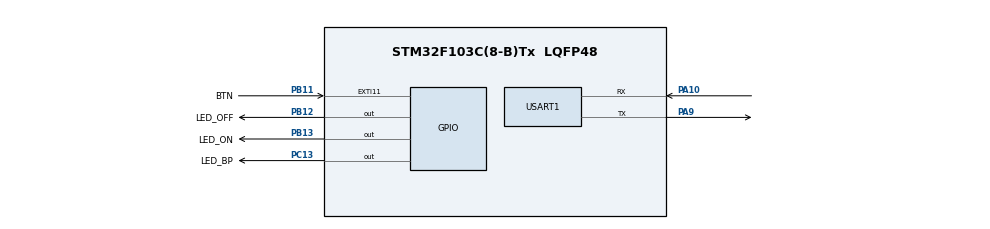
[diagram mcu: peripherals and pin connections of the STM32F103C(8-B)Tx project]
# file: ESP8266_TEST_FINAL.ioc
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FREERTOS.Tasks01=defaultTask,24,128,StartDefaultTask,Default,NULL,Dynamic,NULL,NULL
FREERTOS.configTOTAL_HEAP_SIZE=8000
FREERTOS.configUSE_NEWLIB_REENTRANT=1
FREERTOS.configUSE_TICKLESS_IDLE=1
Mcu.Family=STM32F1
Mcu.Name=STM32F103C(8-B)Tx
Mcu.Package=LQFP48
NVIC.EXTI15_10_IRQn=true\:5\:0\:false\:false\:true\:true\:true\:true\:true
NVIC.PriorityGroup=NVIC_PRIORITYGROUP_4
NVIC.TIM1_UP_IRQn=true\:15\:0\:false\:false\:true\:false\:false\:true\:true
NVIC.TimeBase=TIM1_UP_IRQn
NVIC.TimeBaseIP=TIM1
NVIC.USART1_IRQn=true\:5\:0\:false\:false\:true\:true\:true\:true\:true
PA10.Mode=Asynchronous
PA10.Signal=USART1_RX
PA13.Mode=Serial_Wire
PA13.Signal=SYS_JTMS-SWDIO
PA14.Mode=Serial_Wire
PA14.Signal=SYS_JTCK-SWCLK
PA9.Mode=Asynchronous
PA9.Signal=USART1_TX
PB11.GPIO_Label=BTN
PB11.GPIO_PuPd=GPIO_PULLDOWN
PB11.Signal=GPXTI11
PB12.GPIO_Label=LED_OFF
PB12.Signal=GPIO_Output
PB13.GPIO_Label=LED_ON
PB13.Signal=GPIO_Output
PC13-TAMPER-RTC.GPIO_Label=LED_BP
PC13-TAMPER-RTC.Signal=GPIO_Output
PC14-OSC32_IN.Mode=LSE-External-Oscillator
PC14-OSC32_IN.Signal=RCC_OSC32_IN
PC15-OSC32_OUT.Mode=LSE-External-Oscillator
PC15-OSC32_OUT.Signal=RCC_OSC32_OUT
PD0-OSC_IN.Mode=HSE-External-Oscillator
PD0-OSC_IN.Signal=RCC_OSC_IN
PD1-OSC_OUT.Mode=HSE-External-Oscillator
PD1-OSC_OUT.Signal=RCC_OSC_OUT
ProjectManager.HeapSize=0x200
ProjectManager.StackSize=0x400
ProjectManager.TargetToolchain=STM32CubeIDE
RCC.APB1Freq_Value=8000000
RCC.APB2Freq_Value=8000000
USART1.VirtualMode=VM_ASYNC
VP_FREERTOS_VS_CMSIS_V2.Mode=CMSIS_V2
VP_SYS_VS_tim1.Mode=TIM1
board=custom

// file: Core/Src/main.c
/* USER CODE BEGIN Header */
/**
  ******************************************************************************
  * @file           : main.c
  * @brief          : Main program body
  ******************************************************************************
  * @attention
  *
  * Copyright (c) 2025 STMicroelectronics.
  * All rights reserved.
  *
  * This software is licensed under terms that can be found in the LICENSE file
  * in the root directory of this software component.
  * If no LICENSE file comes with this software, it is provided AS-IS.
  *
  ******************************************************************************
  */
/* USER CODE END Header */
#include "main.h"
#include "cmsis_os.h"

/* USER CODE BEGIN Includes */
#include "esp8266.h"
/* USER CODE END Includes */

UART_HandleTypeDef huart1;

/* Definitions for defaultTask */
osThreadId_t defaultTaskHandle;
const osThreadAttr_t defaultTask_attributes = {
  .name = "defaultTask",
  .stack_size = 128 * 4,
  .priority = (osPriority_t) osPriorityNormal,
};

void SystemClock_Config(void);
static void MX_GPIO_Init(void);
static void MX_USART1_UART_Init(void);
void StartDefaultTask(void *argument);

int main(void)
{

  /* MCU Configuration--------------------------------------------------------*/

  /* Reset of all peripherals, Initializes the Flash interface and the Systick. */
  HAL_Init();

  /* Configure the system clock */
  SystemClock_Config();

  /* Initialize all configured peripherals */
  MX_GPIO_Init();
  MX_USART1_UART_Init();
  /* USER CODE BEGIN 2 */
  esp8266_init();
  /* USER CODE END 2 */

  /* Init scheduler */
  osKernelInitialize();

  /* Create the thread(s) */
  /* creation of defaultTask */
  defaultTaskHandle = osThreadNew(StartDefaultTask, NULL, &defaultTask_attributes);

  /* Start scheduler */
  osKernelStart();

  /* We should never get here as control is now taken by the scheduler */

  /* Infinite loop */
  while (1)
  {

  }
}

void SystemClock_Config(void)
{
  RCC_OscInitTypeDef RCC_OscInitStruct = {0};
  RCC_ClkInitTypeDef RCC_ClkInitStruct = {0};

  /** Initializes the RCC Oscillators according to the specified parameters
  * in the RCC_OscInitTypeDef structure.
  */
  RCC_OscInitStruct.OscillatorType = RCC_OSCILLATORTYPE_HSI;
  RCC_OscInitStruct.HSIState = RCC_HSI_ON;
  RCC_OscInitStruct.HSICalibrationValue = RCC_HSICALIBRATION_DEFAULT;
  RCC_OscInitStruct.PLL.PLLState = RCC_PLL_NONE;
  if (HAL_RCC_OscConfig(&RCC_OscInitStruct) != HAL_OK)
  {
    Error_Handler();
  }

  /** Initializes the CPU, AHB and APB buses clocks
  */
  RCC_ClkInitStruct.ClockType = RCC_CLOCKTYPE_HCLK|RCC_CLOCKTYPE_SYSCLK
                              |RCC_CLOCKTYPE_PCLK1|RCC_CLOCKTYPE_PCLK2;
  RCC_ClkInitStruct.SYSCLKSource = RCC_SYSCLKSOURCE_HSI;
  RCC_ClkInitStruct.AHBCLKDivider = RCC_SYSCLK_DIV1;
  RCC_ClkInitStruct.APB1CLKDivider = RCC_HCLK_DIV1;
  RCC_ClkInitStruct.APB2CLKDivider = RCC_HCLK_DIV1;

  if (HAL_RCC_ClockConfig(&RCC_ClkInitStruct, FLASH_LATENCY_0) != HAL_OK)
  {
    Error_Handler();
  }
}

static void MX_USART1_UART_Init(void)
{

  huart1.Instance = USART1;
  huart1.Init.BaudRate = 115200;
  huart1.Init.WordLength = UART_WORDLENGTH_8B;
  huart1.Init.StopBits = UART_STOPBITS_1;
  huart1.Init.Parity = UART_PARITY_NONE;
  huart1.Init.Mode = UART_MODE_TX_RX;
  huart1.Init.HwFlowCtl = UART_HWCONTROL_NONE;
  huart1.Init.OverSampling = UART_OVERSAMPLING_16;
  if (HAL_UART_Init(&huart1) != HAL_OK)
  {
    Error_Handler();
  }

}

static void MX_GPIO_Init(void)
{
  GPIO_InitTypeDef GPIO_InitStruct = {0};

  /* GPIO Ports Clock Enable */
  __HAL_RCC_GPIOC_CLK_ENABLE();
  __HAL_RCC_GPIOD_CLK_ENABLE();
  __HAL_RCC_GPIOB_CLK_ENABLE();
  __HAL_RCC_GPIOA_CLK_ENABLE();

  /*Configure GPIO pin Output Level */
  HAL_GPIO_WritePin(LED_BP_GPIO_Port, LED_BP_Pin, GPIO_PIN_RESET);

  /*Configure GPIO pin Output Level */
  HAL_GPIO_WritePin(GPIOB, LED_OFF_Pin|LED_ON_Pin, GPIO_PIN_RESET);

  /*Configure GPIO pin : LED_BP_Pin */
  GPIO_InitStruct.Pin = LED_BP_Pin;
  GPIO_InitStruct.Mode = GPIO_MODE_OUTPUT_PP;
  GPIO_InitStruct.Pull = GPIO_NOPULL;
  GPIO_InitStruct.Speed = GPIO_SPEED_FREQ_LOW;
  HAL_GPIO_Init(LED_BP_GPIO_Port, &GPIO_InitStruct);

  /*Configure GPIO pin : BTN_Pin */
  GPIO_InitStruct.Pin = BTN_Pin;
  GPIO_InitStruct.Mode = GPIO_MODE_IT_RISING;
  GPIO_InitStruct.Pull = GPIO_PULLDOWN;
  HAL_GPIO_Init(BTN_GPIO_Port, &GPIO_InitStruct);

  /*Configure GPIO pins : LED_OFF_Pin LED_ON_Pin */
  GPIO_InitStruct.Pin = LED_OFF_Pin|LED_ON_Pin;
  GPIO_InitStruct.Mode = GPIO_MODE_OUTPUT_PP;
  GPIO_InitStruct.Pull = GPIO_NOPULL;
  GPIO_InitStruct.Speed = GPIO_SPEED_FREQ_LOW;
  HAL_GPIO_Init(GPIOB, &GPIO_InitStruct);

  /* EXTI interrupt init*/
  HAL_NVIC_SetPriority(EXTI15_10_IRQn, 5, 0);
  HAL_NVIC_EnableIRQ(EXTI15_10_IRQn);

}

void StartDefaultTask(void *argument)
{
  /* USER CODE BEGIN 5 */
  /* Infinite loop */
  for(;;)
  {
	HAL_GPIO_TogglePin(LED_BP_GPIO_Port, LED_BP_Pin);
    osDelay(250);
  }
  /* USER CODE END 5 */
}

void HAL_TIM_PeriodElapsedCallback(TIM_HandleTypeDef *htim)
{
  if (htim->Instance == TIM1)
  {
    HAL_IncTick();
  }
}

void Error_Handler(void)
{
  __disable_irq();
  while (1)
  {
  }
}
